AUTOSAR XML (schema 4-3-0)
package /CanCom
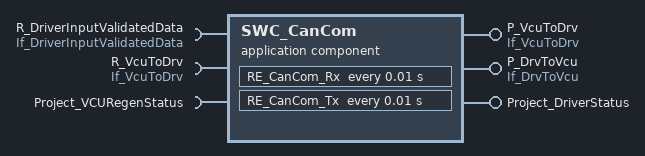
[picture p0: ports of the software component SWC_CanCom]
  application sw component type SWC_CanCom
    provide port P_VcuToDrv: provided-interface=If_VcuToDrv
    provide port P_DrvToVcu: provided-interface=If_DrvToVcu
    require port R_DriverInputValidatedData: required-interface=If_DriverInputValidatedData
    require port R_VcuToDrv: required-interface=If_VcuToDrv
    provide port Project_DriverStatus: provided-interface=Project_DriverStatus
      provided-com-specs:
        data-element=VehicleSpeed, network-representation=compu-method=ISignal_Project_DriverStatus_VehicleSpeed
        data-element=AccelSw, network-representation=compu-method=ISignal_Project_DriverStatus_AccelSw
        data-element=DriverInputFault, network-representation=compu-method=ISignal_Project_DriverStatus_DriverInputFault
        data-element=SocLevel, network-representation=compu-method=ISignal_Project_DriverStatus_SocLevel
        data-element=AliveCounter, network-representation=compu-method=ISignal_Project_DriverStatus_AliveCounter
        data-element=BrakeSw, network-representation=compu-method=ISignal_Project_DriverStatus_BrakeSw
    require port Project_VCURegenStatus: required-interface=Project_VCURegenStatus
      required-com-specs:
        data-element=RegenEnable, network-representation=compu-method=ISignal_Project_VCURegenStatus_RegenEnable
        data-element=LimitReason, network-representation=compu-method=ISignal_Project_VCURegenStatus_LimitReason
        data-element=RegenLevel, network-representation=compu-method=ISignal_Project_VCURegenStatus_RegenLevel
    behavior InternalBehavior
      timing event TE_RE_CanCom_Rx: start-on-event=RE_CanCom_Rx, period=0.01
      timing event TE_RE_CanCom_Tx: start-on-event=RE_CanCom_Tx, period=0.01
      runnable RE_CanCom_Tx: symbol=CanCom_Tx_func
        data-send-points:
          6 x access, all with scope=COMMUNICATION-INTER-ECU:
            DSP_RE_CanCom_Tx_Project_DriverStatus_VehicleSpeed: accessed-variable=Project_DriverStatus.VehicleSpeed
            DSP_RE_CanCom_Tx_Project_DriverStatus_AccelSw: accessed-variable=Project_DriverStatus.AccelSw
            DSP_RE_CanCom_Tx_Project_DriverStatus_DriverInputFault: accessed-variable=Project_DriverStatus.DriverInputFault
            DSP_RE_CanCom_Tx_Project_DriverStatus_SocLevel: accessed-variable=Project_DriverStatus.SocLevel
            DSP_RE_CanCom_Tx_Project_DriverStatus_AliveCounter: accessed-variable=Project_DriverStatus.AliveCounter
            DSP_RE_CanCom_Tx_Project_DriverStatus_BrakeSw: accessed-variable=Project_DriverStatus.BrakeSw
      runnable RE_CanCom_Rx: symbol=CanCom_Rx_func
  application sw component type SWC_InputDiag
    provide port P_DriverInputValidatedData: provided-interface=If_DriverInputValidatedData
    behavior InternalBehavior
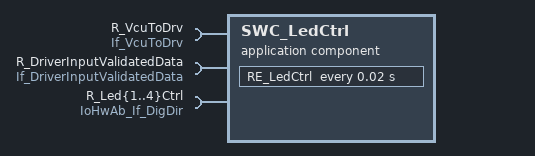
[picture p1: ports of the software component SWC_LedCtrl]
  application sw component type SWC_LedCtrl
    6 x require port:
      R_VcuToDrv: required-com-specs=[RegenLevel, RegenEnable, LimitReason], required-interface=If_VcuToDrv
      R_DriverInputValidatedData: nonqueued-receiver-com-spec=DriverInputFault, required-interface=If_DriverInputValidatedData
      R_Led{1..4}Ctrl: client-com-spec=WriteDirect, required-interface=IoHwAb_If_DigDir
    behavior InternalBehavior
      timing event TE_RE_LedCtrl: start-on-event=RE_LedCtrl, period=0.02
      runnable RE_LedCtrl: symbol=LedCtrl_func
        data-receive-point-by-arguments:
          access DRPBA_RE_LedCtrl_R_DriverInputValidatedData_DriverInputFault: accessed-variable=R_DriverInputValidatedData.DriverInputFault, scope=COMMUNICATION-INTER-ECU
          access DRPBA_RE_LedCtrl_R_VcuToDrv_RegenEnable: accessed-variable=R_VcuToDrv.RegenEnable, scope=COMMUNICATION-INTER-ECU
          access DRPBA_RE_LedCtrl_R_VcuToDrv_RegenLevel: accessed-variable=R_VcuToDrv.RegenLevel, scope=COMMUNICATION-INTER-ECU
        4 x sync call:
          SSCP_RE_LedCtrl_R_LedCtrl_WriteDirect: operation=R_Led1Ctrl.WriteDirect
          SSCP_RE_LedCtrl_R_Led{2..4}Ctrl_WriteDirect: operation=R_Led{2..4}Ctrl.WriteDirect
